# ulp_core_model: IP-XACT component
VLNV IcronTechnologies:IcronTechnologies:ulp_core_model:1.0

## Parameters
addr_width = 9
bus_width = 32

## Bus interfaces (logical=physical port)
default_map: slave AGNISYS:AGNISYS:APB:1.0, memory map ulp_coremap
  pclk=pclk, presetn=presetn, psel=psel, penable=penable, pwrite=pwrite, pprot=pprot, pstrb=pstrb, pwdata=pwdata, paddr=paddr, pready=pready, prdata=prdata, pslverr=pslverr

## Ports
in pclk
in presetn
in psel
in penable
in pwrite
in pprot[2:0]
in pstrb[(bus_width div 8 )-1:0]
in pwdata[bus_width -1:0]
in paddr[addr_width -1:0]
out pready
out prdata[bus_width -1:0]
out pslverr
out ulp_core_regsversion_major_r[7:0]
out ulp_core_regsversion_minor_r[7:0]
out ulp_core_regsversion_patch_r[7:0]
out ulp_core_regsconfiguration_enb
out ulp_core_regsconfiguration_credit_hp_timer_en_r
out ulp_core_regsconfiguration_pending_hp_timer_en_r
out ulp_core_regsconfiguration_internal_loopback_en_r
out ulp_core_regsconfiguration_quasi_ss_disabled_mode_r
out ulp_core_regsconfiguration_quasi_u3_mode_r
out ulp_core_regsconfiguration_allow_u2_r
out ulp_core_regsconfiguration_allow_u1_r
out ulp_core_regsconfiguration_dfp_compliance_mode_en_r
out ulp_core_regsconfiguration_use_trx_detect_quiet_dfp_max_r
out ulp_core_regscontrol_enb
out ulp_core_regscontrol_wait_in_polling_lfps_r
out ulp_core_regscontrol_exit_low_power_r
in ulp_core_regscontrol_exit_low_power_hw_clear
out ulp_core_regscontrol_wait_in_u3_r
out ulp_core_regscontrol_wait_in_u1_u2_r
out ulp_core_regscontrol_delay_u3_wakeup_r
out ulp_core_regscontrol_go_u{n}_r (n=1..3)
in ulp_core_regscontrol_go_u{n}_hw_clear (n=1..3)
out ulp_core_regscontrol_wait_in_hot_reset_r
out ulp_core_regscontrol_gen_warm_reset_r
in ulp_core_regscontrol_gen_warm_reset_hw_clear
out ulp_core_regscontrol_allow_rx_term_en_hw_clr_r
out ulp_core_regscontrol_rx_termination_en_r
in ulp_core_regscontrol_rx_termination_en_hw_clear
out ulp_core_regscontrol_go2_ss_inactive_r
in ulp_core_regscontrol_go2_ss_inactive_hw_clear
out ulp_core_regscontrol_go2_recovery_r
in ulp_core_regscontrol_go2_recovery_hw_clear
out ulp_core_regscontrol_go2_hot_reset_r
in ulp_core_regscontrol_go2_hot_reset_hw_clear
out ulp_core_regscontrol_go2_loopback_r
in ulp_core_regscontrol_go2_loopback_hw_clear
out ulp_core_regscontrol_go2_ss_disabled_r
in ulp_core_regscontrol_go2_ss_disabled_hw_clear
out ulp_core_regscontrol_disable_scrambling_r
out ulp_core_regscontrol_set_ts2_disable_scramble_bit_r
out ulp_core_regscontrol_set_ts2_loopbk_bit_r
out ulp_core_regscontrol_set_ts2_link_config_field_r
out ulp_core_regscontrol_go2_rx_detect_r
in ulp_core_regscontrol_go2_rx_detect_hw_clear
out ulp_core_regstimer_correction_enb
out ulp_core_regstimer_correction_add_2_cht_r[4:0]
out ulp_core_regstimer_correction_add_2_pht_r[4:0]
in ulp_core_regsltssm_state_main_state_in[3:0]
in ulp_core_regsltssm_state_main_state_in_enb
in ulp_core_regsltssm_state_sub_state_in[3:0]
in ulp_core_regsltssm_state_sub_state_in_enb
out ulp_core_regsstats0_rd2clr_config_rd_valid_out
out ulp_core_regsstats0_rd2clr_config_wr_valid_out
out ulp_core_regsstats0_tx_lfps_cnt_in_err_rd_valid_out
out ulp_core_regsstats0_rx_lfps_cnt_in_err_rd_valid_out
out ulp_core_regsstats0_tx_framer_ptp_violated_rd_valid_out
out ulp_core_regsstats0_link_training_ptp_violated_rd_valid_out
out ulp_core_regsstats0_link_command_ptp_violated_rd_valid_out
out ulp_core_regsstats0_lmp_ptp_violated_rd_valid_out
out ulp_core_regsstats0_link_command_rx_event_fifo_overflow_rd_valid_out
out ulp_core_regsstats0_link_command_rx_event_fifo_underflow_rd_valid_out
out ulp_core_regsstats0_lmp_rx_event_fifo_overflow_rd_valid_out
out ulp_core_regsstats0_lmp_rx_event_fifo_underflow_rd_valid_out
out ulp_core_regsstats0_remote_rx_hdr_buff_crdt_cnt_in_err_rd_valid_out
out ulp_core_regsstats0_to_phy_out_sop_rd_valid_out
out ulp_core_regsstats0_to_phy_out_eop_rd_valid_out
out ulp_core_regsstats0_go2_u0_from_recovery_rd_valid_out
out ulp_core_regsstats0_rx_go_recovery_rd_valid_out
out ulp_core_regsstats0_snt_lrty_rd_valid_out
out ulp_core_regsstats0_snt_lbad_rd_valid_out
out ulp_core_regsstats0_rcvd_lrty_rd_valid_out
out ulp_core_regsstats0_rcvd_lbad_rd_valid_out
out ulp_core_regsptp_guard_2core_config0_fix_ptp_violations_enb
out ulp_core_regsptp_guard_2core_config0_fix_ptp_violations_activate_r
out ulp_core_regsptp_guard_2core_config0_max_cycles_enb
out ulp_core_regsptp_guard_2core_config0_max_cycles_max_cycle_mode_r[3:0]
out ulp_core_regsptp_guard_2core_config0_max_cycles_max_cycles_r[15:0]
out ulp_core_regsptp_guard_2core_stats0_rd2clr_config_rd_valid_out
out ulp_core_regsptp_guard_2core_stats0_rd2clr_config_wr_valid_out
out ulp_core_regsptp_guard_2core_stats0_missing_sop_err_rd_valid_out
out ulp_core_regsptp_guard_2core_stats0_missing_eop_err_rd_valid_out
out ulp_core_regsptp_guard_2core_stats0_max_cycle_err_rd_valid_out
out ulp_core_regsptp_guard_2phy_config0_fix_ptp_violations_enb
out ulp_core_regsptp_guard_2phy_config0_fix_ptp_violations_activate_r
out ulp_core_regsptp_guard_2phy_config0_max_cycles_enb
out ulp_core_regsptp_guard_2phy_config0_max_cycles_max_cycle_mode_r[3:0]
out ulp_core_regsptp_guard_2phy_config0_max_cycles_max_cycles_r[15:0]
out ulp_core_regsptp_guard_2phy_stats0_rd2clr_config_rd_valid_out
out ulp_core_regsptp_guard_2phy_stats0_rd2clr_config_wr_valid_out
out ulp_core_regsptp_guard_2phy_stats0_missing_sop_err_rd_valid_out
out ulp_core_regsptp_guard_2phy_stats0_missing_eop_err_rd_valid_out
out ulp_core_regsptp_guard_2phy_stats0_max_cycle_err_rd_valid_out

## Address spaces and blocks
ulp_coremap.ulp_core: base 0x000, range 0x200, width 32

## Registers
Registers are 32-bit, read-only, reset 0x0 unless marked. A register's access mark holds for its fields unless they carry their own. Offsets are from the block's base; lines under a group give offsets from that group; [hi:lo] are bit positions; {n}, {i} and the like mark numbered series; 'fields as' and 'values as' point back to an identical list; <NAME> marks a mode.

## ulp_coremap.ulp_core — ULP Registers
Base 0x00000000
0x00 version reset 0x90000 — 8.0.1: Cleanup and add synchronizer to phy_reset_n to avoid direct path to the output pad 8.1.0: Changed the Interrupt Pending to avoid blocking the register update when enable is 0 8.2.0: Added pending_irq register 8.3.0: Fixed Hot Reset bug; Added in_u0 to the 'rdy' to the top level; Bring in_hot_reset and in_warm_reset to upper layer 8.3.1: Cap Remote RX Credit Count to 4 8.4.0: Changed from Logic to Wire for ift_ulp_pipe 8.5.0: Add Timer Corrections 8.5.1: Bug fixes 8.5.2: Bug fixes (5466, 4724, 4808) 8.5.3: Address timing issues for previous fix 8.5.4: Infinite Loop and signal reset assignment missing fixed 9.0.0: Many Enhancement and bug fixes for LFPS, Polarity Detection, RX Detect, data exception handing, U3 wakeup, register operations, etc
  [23:16] major — Major version
  [15:8] minor — Minor version
  [7:0] patch — Patch version
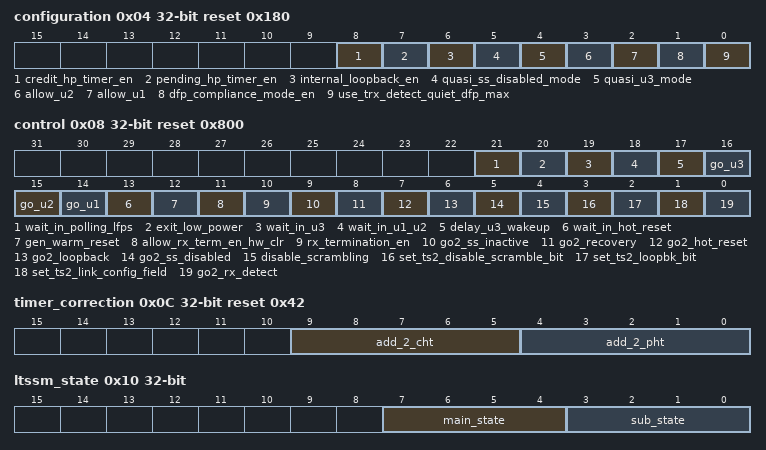
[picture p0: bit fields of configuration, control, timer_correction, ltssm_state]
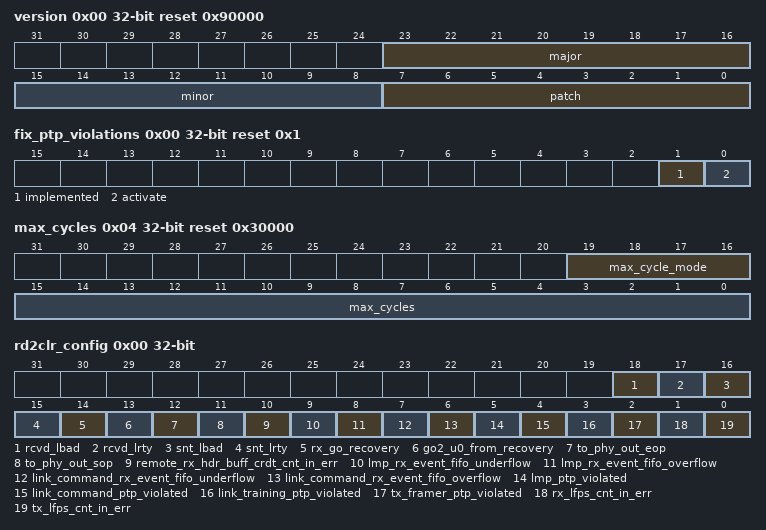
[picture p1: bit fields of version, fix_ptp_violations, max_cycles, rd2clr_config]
0x04 configuration rw reset 0x180
  [8] credit_hp_timer_en — When 1, it enables the Credit_HP_Timer
  [7] pending_hp_timer_en — When 1, it enables the Pending_HP_Timer
  [6] internal_loopback_en — When 1 it enables an RX Loopback (Section 6.8.4) implementation in the USB Link Layer rather than the PHY
  [5] quasi_ss_disabled_mode — When 1, it puts the USB PHY into P2 power mode rather than the normal P3 as required by the Standard
  [4] quasi_u3_mode — When 1, it handshakes U3 protocol with the USB partner but puts the USB PHY into P2 low power mode. This mode could be used for debugging, or in case of any bug in normal U3 mode as USB PHY PCLK is removed in U3
  [3] allow_u2 — Assert high to allow U2 Low Power request to be processed. When low, it will always issue LXU. Section 7.2.4.2.3 Item 3
  [2] allow_u1 — Assert high to allow U1 Low Power request to be processed. When low, it will always issue LXU. Section 7.2.4.2.3 Item 3
  [1] dfp_compliance_mode_en — Section 7.5.4.3.1 Item 4: A downstream port shall enable its transition path to Compliance Mode, if directed
  [0] use_trx_detect_quiet_dfp_max — Section 7.5.3.7.1 and Table 7-12 (Note 1): Implementations are recommended to consider system states when choosing when to use a larger value of the tRxDetectQuietTimeoutDFP timer. Using a smaller value when the system is active and a larger value when the system is in a standby/sleep or other idle state allows for higher responsiveness to connect events during active states while enabling power savings in an idle system state.
0x08 control rw reset 0x800
  [21] wait_in_polling_lfps — When 1, it instructs the port to wait in Polling.LFPS. Note this wait is NOT based on standard but only for LEX/REX extension benefit. Also note the 360 ms timer of this state
  [20] exit_low_power — Assert high to initiate exit from U1, U2, or U3 Low Power. Section 7.2.4.2.7 and Sections 7.5.8.2 Item 7, 7.5.8.2 Item 6, and 7.5.9.2 Item 5 Write a 1 and HW clears
  [19] wait_in_u3 — When set, allows the software to hold the port in its exit handshaking (either initiated by link partner or self initiated) to come out U3 following Section 7.2.4.2.7. Note the limit time based on Table 6-30 in Section 6.9.2. A 20ms for U3 (t13-t10)
  [18] wait_in_u1_u2 — When set, allow the software to hold the port in its exit handshaking (either initiated by link partner or self initiated) to come out U1, U2 following Section 7.2.4.2.7. Note the limit time based on Table 6-30 in Section 6.9.2. A 2ms for U1/U2 (t13-t10)
  [17] delay_u3_wakeup — Assert high to delay the start of the wakeup. This applies to both when the port is Master (initiating) of U3 wakeup or Slave (responding) to U3 wakeup. In effect, it will delay t10 of Figure 6-30 when it is Master or t11 when it is Slave. NOTE: If this bit is set when the port is a master of wakeup and remains asserted, it will result in squelching the wakeup LFPS. If it remains asserted for over 10ms, an interrupt is issued informing software of a wakeup failure, as the Slave will never see wakeup to be able to respond. Both ports will remain in U3. In this configuration, this bit can be used as a test bit as well. If this bit is et when the port is a slave of wakeup and remains asserted, the master port will see a tNOLFPSReponseTimeout and both ports remain in U3. In this configuration, this bit can be used as a test bit.
  [16] go_u3 — Assert high to initiate a U3 Low Power when in U0. Section 7.2.4.2.3 and Section 7.5.6.2 Item 3 NOTE: This can only be done when it is a downstream port. Otherwise, no action is taken Write a 1 and HW clears it
  [15] go_u2 — Assert high to initiate a U2 Low Power when in U0. Section 7.2.4.2.3 and Section 7.5.6.2 Item 2 Write a 1 and HW clears it
  [14] go_u1 — Assert high to initiate a U1 Low Power when in U0. Section 7.2.4.2.3 and Section 7.5.6.2 Item 1 Write a 1 and HW clears it
  [13] wait_in_hot_reset — When set, allows the software to kepp the port in hot reset whenever it enters and, thus, prevents the handshake of HotReset.Active in Section 7.5.12.3.2 to complete. Note the 12 ms timer for tHotResetActiveTimeout as the LTSSM will slip into eSS.Inactive from the Hot Reset state on expiry of this timer
  [12] gen_warm_reset — Section 6.9.3: A downstream port may issue a Warm Reset at any Link states except SS.Disabled. See also 10.3.1.6, the Resetting State of a Downstream Port Write a 1 and HW clears it
  [11] allow_rx_term_en_hw_clr — When set to 1, it allows the Hardware to self clear rx_termination_en when entering back into rx_termination reset. When set to 0, the hardware does not clear rx_termination_en bit at any time.
  [10] rx_termination_en — Enable presenting ULP RX termination. Set to 1 when the port is to present its RX Termination to the USB partner. Writing a 0, will remove the termination to the USB partner and enables a "stealth mode". HW clears this bit (when allow_rx_term_en_hw_clr is asserted) when the LTSSM goes into the RX.Detect.Reset
  [9] go2_ss_inactive — Section 7.5.6.2 Item 10, A downstream port shall transition to eSS.Inactive when directed Write a 1 and HW clears it
  [8] go2_recovery — Section 7.5.6.2 Item 7: The port shall transition to Recovery when directed Write a 1 and HW clears it
  [7] go2_hot_reset — Section 7.5.10.5.2 Item 5: A downstream port shall transition to Hot Reset when directed Write a 1 and HW clears it when completed the action
  [6] go2_loopback — Section 7.5.4.10.2 Item 1, 7.5.10.5.2 Item 1: The port shall transition to Loopback when directed as a loopback master and the port is capable of being a loopback master Write a 1 and HW clears it when completed the action NOTE: Not Implemented, as we are always a loopback slave
  [5] go2_ss_disabled — Sections 7.5.6.2 Item 11 , 7.5.2.3.2 , 7.5.3.3.2, 7.5.3.6, 7.5.3.7.2, 7.5.4.3.2, 7.5.4.7.2, 7.5.4.8.2 Item 10, 7.5.4.9.2 Item 10, 7.5.4.10.2 Item 6, 7.5.6.2 Item 9, 7.5.6.2 Item 11, 7.5.10.3.2 Item 5, 7.5.10.4.2 Item 5, 7.5.10.5.2 Item 6 Write a 1 and HW clears it.
  [4] disable_scrambling — Section 7.5.4.10.1 Item 5: ( This is for the TX Scrambler) The port in SuperSpeed operation shall disable the scrambling if directed
  [3] set_ts2_disable_scramble_bit — Section 7.5.4.9.1 Item 1.3: When directed, the port shall set the Disabling Scrambling bit in the TS2 ordered set. This shall eventually be used in the RX De-Scrambler
  [2] set_ts2_loopbk_bit — Not Used -Will be Removed
  [1] set_ts2_link_config_field — Not Used -Will be Removed
  [0] go2_rx_detect — Section 7.5.1.1.2 Item 1: A downstream port shall transition to Rx.Detect when directed Write a 1 and HW clears it.
0x0C timer_correction rw reset 0x42
  [9:5] add_2_cht — Each value adds (2^13)*8 ns (8 is the result of the block running at 125MHz) to the CREDIT_HP_TIMER of Table 7-7. Hence, value of 2 adds 2*8192*8=131.072us
  [4:0] add_2_pht — Each value adds (2^5)*8 ns (8 is the result of the block running at 125MHz) to the PENDING_HP_TIMER of Table 7-7. Hence, value of 2 adds 2*32*8=512ns
0x10 ltssm_state — Shows the LTSSM State at the time
  [7:4] main_state — This is the main state of the LTSSM as listed in the Standard Section 7.5
  [3:0] sub_state — This is the sub state of the LTSSM as listed in the Standard Section 7.5
0x14 stats0 group — All the Statistic Registers and their configuration for the ULP Core Clock
  0x00 rd2clr_config rw — Configures if the stats register read by s/w clears the read register. A 1 in any bit configures the h/w to clear the corresponding stats register after a s/w read of that stats register.
    [18] rcvd_lbad, [17] rcvd_lrty, [16] snt_lbad, [15] snt_lrty, [14] rx_go_recovery, [13] go2_u0_from_recovery, [12] to_phy_out_eop, [11] to_phy_out_sop, [10] remote_rx_hdr_buff_crdt_cnt_in_err, [9] lmp_rx_event_fifo_underflow, [8] lmp_rx_event_fifo_overflow, [7] link_command_rx_event_fifo_underflow, [6] link_command_rx_event_fifo_overflow, [5] lmp_ptp_violated, [4] link_command_ptp_violated, [3] link_training_ptp_violated, [2] tx_framer_ptp_violated, [1] rx_lfps_cnt_in_err, [0] tx_lfps_cnt_in_err
  0x04 tx_lfps_cnt_in_err — Count of the number of TX LFPS counter going beyond the largest value possible
    [7:0] tx_lfps_cnt_in_err
  0x08 rx_lfps_cnt_in_err — Count of the number of RX LFPS counter going beyond the largest value possible
    [7:0] rx_lfps_cnt_in_err
  0x0C tx_framer_ptp_violated — Count the number of PTP Protocol Violation in the TX Frame Manager
    [7:0] tx_framer_ptp_violated — _icron_event_detect_rising_edge_
  0x10 link_training_ptp_violated — Count the number of PTP Protocol Violation in the Link Training Manager
    [7:0] link_training_ptp_violated — _icron_event_detect_rising_edge_
  0x14 link_command_ptp_violated — Count the number of PTP Protocol Violation in the Link Command Manager
    [7:0] link_command_ptp_violated — _icron_event_detect_rising_edge_
  0x18 lmp_ptp_violated — Count the number of PTP Protocol Violation in the LMP Manager
    [7:0] lmp_ptp_violated
  0x1C link_command_rx_event_fifo_overflow — Count the number of Link Command RX Event FIFO Overflow
    [7:0] link_command_rx_event_fifo_overflow
  0x20 link_command_rx_event_fifo_underflow — Count the number of Link Command RX Event FIFO Underflow
    [7:0] link_command_rx_event_fifo_underflow
  0x24 lmp_rx_event_fifo_overflow — Count the number of LMP Manager RX Event FIFO Overflow
    [7:0] lmp_rx_event_fifo_overflow
  0x28 lmp_rx_event_fifo_underflow — Count the number of LMP Manager RX Event FIFO Underflow
    [7:0] lmp_rx_event_fifo_underflow
  0x2C remote_rx_hdr_buff_crdt_cnt_in_err — Count the number of Remote RX Header Buffer Credit Count erroneous increment or decrement
    [7:0] remote_rx_hdr_buff_crdt_cnt_in_err
  0x30 to_phy_out_sop — Count the number of PTP sop to the PHY path
  0x34 to_phy_out_eop — Count the number of PTP eop to the PHY path
  0x38 go2_u0_from_recovery — Count of the number of times LTSSM move from Recovery to U0
    [15:0] go2_u0_from_recovery
  0x3C rx_go_recovery — Count of the number of recovery initiated due to received data from PHY (Section 7.6.6.2 Item 5)
    [15:0] rx_go_recovery
  0x40 snt_lrty — Count of the number of times the ULP has sent LRTY to its partner in response to receiving LBAD from its partner
    [15:0] snt_lrty
  0x44 snt_lbad — Count of the number of times the ULP has sent LBAD to its partner
    [15:0] snt_lbad
  0x48 rcvd_lrty — Count of the number of times the ULP has received LRTY from its partner in response to an earlier ULP sending LBAD
    [15:0] rcvd_lrty
  0x4C rcvd_lbad — Count of the number of times the ULP has received LBAD from its partner
    [15:0] rcvd_lbad
0x64 ptp_guard_2core group
  0x00 version reset 0x30300 — 3.1.0: Fixed bug in Max Cycle Error where in certain mode the cycles were included in the count 3.2.0: Changed the Interrupt Pending to avoid blocking the register update when enable is 0 3.3.0: Added pending_irq register
    fields as version
  0x04 config0 group
    0x00 fix_ptp_violations access per field reset 0x1
      [1] implemented ro — This is the synthesis parameter value used. When 1, it shows the PTP Guard fix logic has been implemented
      [0] activate rw — When 1, and if the fix logic is implemented, it instructs the PTP Guard to fix the PTP violations it detects (and reports). Note that there is a synthesis parameter to generate the "fix" logic or not When 0, no attempt is done to fix (even if the logic exists) and the PTP Guard will only work as a monitor and reports the violations detected. For full details of the operation, what violations are detected and fixed, and how the fix is done, see the wiki.
    0x04 max_cycles rw reset 0x30000
      [19:16] max_cycle_mode — This configures the mode of counting towards max_cycles: 0x0: All PTP cycles are included in the count 0x1: PTP cycles with backpressure (drdy=1'b0) are excluded from the count 0x2: PTP cycles with wait (srdy=1'b0) are excluded from the count 0x3: PTP cycles with either backpressure or wait are excluded from the count. Hence, only "absorbed" PTP cycles are included in the count Other mode values are reserved
      [15:0] max_cycles — Sets the maximum number of clock cycles the PTP packet can last between its sop and eop taking into account the max_cycle_mode When set to 0, it instructs the logic not to fix this violation (when the fix logic is available). However, the monitor will still issue a violation when the cycle count reaches its maximum and rollover.
  0x0C stats0 group — All the Statistic Registers and their configuration
    0x00 rd2clr_config rw — Configures if the stats register read by s/w clears the read register. A 1 in any bit configures the h/w to clear the corresponding stats register after a s/w read of that stats register.
      [2] max_cycle_err, [1] missing_eop_err, [0] missing_sop_err
    0x04 missing_sop_err — Counts the number of PTP violations due to missing sop where the srdy was asserted without a prior sop assertion
      [15:0] missing_sop_err
    0x08 missing_eop_err — Counts the number of PTP violations due to missing eop where the PTP had been started but a new sop is seen without ending the previously started PTP
      [15:0] missing_eop_err
    0x0C max_cycle_err — Counts the number of PTP violations due to reaching the maximum allowed cycles after starting a new PTP
      [15:0] max_cycle_err
  0x1C irq0 group — Define the IRQ group
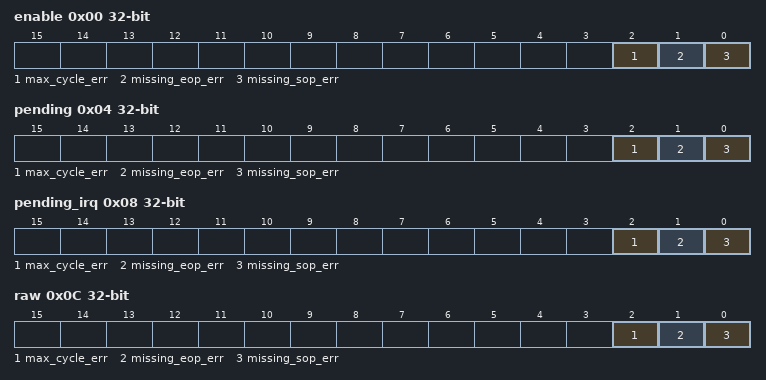
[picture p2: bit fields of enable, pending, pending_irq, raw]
    0x00 enable rw — The enable for the actual interrupt signals. Writing a 1 enables the interrupt.
      [2] max_cycle_err — Fires on PTP violations due to reaching the maximum allowed cycles after starting a new PTP
      [1] missing_eop_err — Fires on PTP violations due to missing eop where the PTP had been started but a new sop is seen without ending the previously started PTP
      [0] missing_sop_err — Fires on PTP violations due to missing sop where the srdy was asserted without a prior sop assertion
    0x04 pending rw — The actual interrupt(s) that has triggered. Write a 1 to clear.
      [2] max_cycle_err write-1-clears, [1] missing_eop_err write-1-clears, [0] missing_sop_err write-1-clears
    0x08 pending_irq — Registered version of pending & enable.
      [2] max_cycle_err, [1] missing_eop_err, [0] missing_sop_err
    0x0C raw — The status registered values for the interrupt signals, if applicable.
      [2] max_cycle_err — Not used
      [1] missing_eop_err — Not used
      [0] missing_sop_err — Not used
0x90 ptp_guard_2phy group
  0x00 version reset 0x30300 — 3.1.0: Fixed bug in Max Cycle Error where in certain mode the cycles were included in the count 3.2.0: Changed the Interrupt Pending to avoid blocking the register update when enable is 0 3.3.0: Added pending_irq register
    fields as version
  0x04 config0 group
    0x00 fix_ptp_violations access per field reset 0x1
      fields as ptp_guard_2core.config0.fix_ptp_violations
    0x04 max_cycles rw reset 0x30000
      fields as ptp_guard_2core.config0.max_cycles
  0x0C stats0 group — All the Statistic Registers and their configuration
    0x00 rd2clr_config rw — Configures if the stats register read by s/w clears the read register. A 1 in any bit configures the h/w to clear the corresponding stats register after a s/w read of that stats register.
      [2] max_cycle_err, [1] missing_eop_err, [0] missing_sop_err
    0x04 missing_sop_err — Counts the number of PTP violations due to missing sop where the srdy was asserted without a prior sop assertion
      [15:0] missing_sop_err
    0x08 missing_eop_err — Counts the number of PTP violations due to missing eop where the PTP had been started but a new sop is seen without ending the previously started PTP
      [15:0] missing_eop_err
    0x0C max_cycle_err — Counts the number of PTP violations due to reaching the maximum allowed cycles after starting a new PTP
      [15:0] max_cycle_err
  0x1C irq0 group — Define the IRQ group
    0x00 enable rw — The enable for the actual interrupt signals. Writing a 1 enables the interrupt.
      fields as ptp_guard_2core.irq0.enable
    0x04 pending rw — The actual interrupt(s) that has triggered. Write a 1 to clear.
      fields as ptp_guard_2core.irq0.pending
    0x08 pending_irq — Registered version of pending & enable.
      [2] max_cycle_err, [1] missing_eop_err, [0] missing_sop_err
    0x0C raw — The status registered values for the interrupt signals, if applicable.
      fields as ptp_guard_2core.irq0.raw
0xBC irq0 group — Define the IRQ group
  0x00 enable rw — The enable for the actual interrupt signals. Writing a 1 enables the interrupt.
    [29] core_clk_mode — Fires when the core clock mode changes from system 125 to the derivative of the PCLK (1/2PCLK) or vice-versa
    [28] u3_exit_completed — Fires when the U1/U2 or U3 wakeup is successfully complete
    [27] u3_as_slave_exit_failed — When Salve of exit, it fires on when U3 wakeup does not complete. This is typically is the case when the port is configured to not start its wakeup LFPS (delay t11 of Figure 6-30) before 10 ms limit.
    [26] u3_as_master_exit_failed — When Master of exit, it fires on when the U1/U2 exit or U3 wakeup does not complete correctly due to tNOLFPSReponseTimeout. --See Section 7.2.4.2.7 Item 5 and Item 6
    [25] u3_exit_initiated — Fires on when a U1/U2 exit or U3 wakeup is received
    [24] in_u3 — Fires on when entered U3
    [23] u3_entry_failed — Fires on when our U3 does not complete and we end up in LTSSM Inactive. (NOT CONNECTED) --see Section 7.2.4.2.4 Item 11
    [22] u3_entry_received — Fires on when a U3 Request is received from the USB partner Note that only a downstream partner will issue U3
    [21] in_u2 — Fires on when entered U2
    [20] u2_entry_rejected — Fires on when our U2 request is rejected by the USB partner
    [19] u2_entry_received — Fires on when a U2 Request is received from the USB partner
    [18] in_u1 — Fires on when entered U1
    [17] u1_entry_rejected — Fires on when our U1 request is rejected by the USB partner
    [16] u1_entry_received — Fires on when a U1 Request is received from the USB partner
    [15] completed_hot_reset — Fires on completing the hot reset
    [14] in_hot_reset — Fires on entry into hot reset
    [13] completed_warm_reset — Fires on completing the warm reset
    [12] in_warm_reset — Fires on entry into warm reset
    [11] rx_termination_det — Fires on changing the state of the USB partner's RX Termination
    [10] remote_rx_hdr_buff_crdt_cnt_in_err — Fires on Remote RX Header Buffer Credit Count erroneous increment or decrement
    [9] lmp_rx_event_fifo_underflow — Fires on LMP Manager RX Event FIFO Underflow
    [8] lmp_rx_event_fifo_overflow — Fires on LMP Manager RX Event FIFO Overflow
    [7] link_command_rx_event_fifo_underflow — Fires on Link Command RX Event FIFO Underflow
    [6] link_command_rx_event_fifo_overflow — Fires on Link Command RX Event FIFO Overflow
    [5] lmp_ptp_violated — Fires on PTP Protocol Violation in the LMP Manager
    [4] link_command_ptp_violated — Fires on PTP Protocol Violation in the Link Command Manager
    [3] link_training_ptp_violated — Fires on PTP Protocol Violation in the Link Training Manager
    [2] tx_framer_ptp_violated — Fires on PTP Protocol Violation in the TX Frame Manager
    [1] rx_lfps_cnt_in_err — Fires on RX LFPS counter going beyond the largest value possible
    [0] tx_lfps_cnt_in_err — Fires on TX LFPS counter going beyond the largest value possible
  0x04 pending rw — The actual interrupt(s) that has triggered. Write a 1 to clear.
    [29] core_clk_mode write-1-clears — Fires when the core clock mode changes from system 125 to the derivative of the PCLK (1/2PCLK) or vice-versa
    [28] u3_exit_completed write-1-clears — Fires when the U1/U2 or U3 wakeup is successfully complete
    [27] u3_as_slave_exit_failed write-1-clears — When Salve of exit, it fires on when U3 wakeup does not complete. This is typically is the case when the port is configured to not start its wakeup LFPS (delay t11 of Figure 6-30) before 10 ms limit.
    [26] u3_as_master_exit_failed write-1-clears — When Master of exit, it fires on when the U1/U2 exit or U3 wakeup does not complete correctly due to tNOLFPSReponseTimeout. --See Section 7.2.4.2.7 Item 5 and Item 6
    [25] u3_exit_initiated write-1-clears — Fires on when a U1/U2 exit or U3 wakeup is received
    [24] in_u3 write-1-clears — Fires on when entered U3
    [23] u3_entry_failed write-1-clears — Fires on when our U3 does not complete and we end up in LTSSM Inactive --see Section 7.2.4.2.4 Item 11
    [22] u3_entry_received write-1-clears — Fires on when a U3 Request is received from the USB partner Note that only a downstream partner will issue U3
    [21] in_u2 write-1-clears — Fires on when entered U2
    [20] u2_entry_rejected write-1-clears — Fires on when our U2 request is rejected by the USB partner
    [19] u2_entry_received write-1-clears — Fires on when a U2 Request is received from the USB partner
    [18] in_u1 write-1-clears — Fires on when entered U1
    [17] u1_entry_rejected write-1-clears — Fires on when our U1 request is rejected by the USB partner
    [16] u1_entry_received write-1-clears — Fires on when a U1 Request is received from the USB partner
    [15] completed_hot_reset write-1-clears — Fires on completing the hot reset
    [14] in_hot_reset write-1-clears — Fires on entry into hot reset
    [13] completed_warm_reset write-1-clears — Fires on completing the warm reset
    [12] in_warm_reset write-1-clears — Fires on entry into warm reset
    [11] rx_termination_det write-1-clears — Fires on changing the state of the USB partner's RX Termination
    [10] remote_rx_hdr_buff_crdt_cnt_in_err write-1-clears — Fires on Remote RX Header Buffer Credit Count erroneous increment or decrement
    [9] lmp_rx_event_fifo_underflow write-1-clears — Fires on LMP Manager RX Event FIFO Underflow
    [8] lmp_rx_event_fifo_overflow write-1-clears — Fires on LMP Manager RX Event FIFO Overflow
    [7] link_command_rx_event_fifo_underflow write-1-clears — Fires on Link Command RX Event FIFO Underflow
    [6] link_command_rx_event_fifo_overflow write-1-clears — Fires on Link Command RX Event FIFO Overflow
    [5] lmp_ptp_violated write-1-clears — Fires on PTP Protocol Violation in the LMP Manager
    [4] link_command_ptp_violated write-1-clears — Fires on PTP Protocol Violation in the Link Command Manager
    [3] link_training_ptp_violated write-1-clears — Fires on PTP Protocol Violation in the Link Training Manager
    [2] tx_framer_ptp_violated write-1-clears — Fires on PTP Protocol Violation in the TX Frame Manager
    [1] rx_lfps_cnt_in_err write-1-clears — Fires on RX LFPS counter going beyond the largest value possible
    [0] tx_lfps_cnt_in_err write-1-clears — Fires on TX LFPS counter going beyond the largest value possible
  0x08 pending_irq — Registered version of pending & enable
    [29] core_clk_mode — Fires when the core clock mode changes from system 125 to the derivative of the PCLK (1/2PCLK) or vice-versa
    [28] u3_exit_completed — Fires when the U1/U2 or U3 wakeup is successfully complete
    [27] u3_as_slave_exit_failed — When Salve of exit, it fires on when U3 wakeup does not complete. This is typically is the case when the port is configured to not start its wakeup LFPS (delay t11 of Figure 6-30) before 10 ms limit.
    [26] u3_as_master_exit_failed — When Master of exit, it fires on when the U1/U2 exit or U3 wakeup does not complete correctly due to tNOLFPSReponseTimeout. --See Section 7.2.4.2.7 Item 5 and Item 6
    [25] u3_exit_initiated — Fires on when a U1/U2 exit or U3 wakeup is received
    [24] in_u3 — Fires on when entered U3
    [23] u3_entry_failed — Fires on when our U3 does not complete and we end up in LTSSM Inactive --see Section 7.2.4.2.4 Item 11
    [22] u3_entry_received — Fires on when a U3 Request is received from the USB partner Note that only a downstream partner will issue U3
    [21] in_u2 — Fires on when entered U2
    [20] u2_entry_rejected — Fires on when our U2 request is rejected by the USB partner
    [19] u2_entry_received — Fires on when a U2 Request is received from the USB partner
    [18] in_u1 — Fires on when entered U1
    [17] u1_entry_rejected — Fires on when our U1 request is rejected by the USB partner
    [16] u1_entry_received — Fires on when a U1 Request is received from the USB partner
    [15] completed_hot_reset — Fires on completing the hot reset
    [14] in_hot_reset — Fires on entry into hot reset
    [13] completed_warm_reset — Fires on completing the warm reset
    [12] in_warm_reset — Fires on entry into warm reset
    [11] rx_termination_det — Fires on changing the state of the USB partner's RX Termination
    [10] remote_rx_hdr_buff_crdt_cnt_in_err — Fires on Remote RX Header Buffer Credit Count erroneous increment or decrement
    [9] lmp_rx_event_fifo_underflow — Fires on LMP Manager RX Event FIFO Underflow
    [8] lmp_rx_event_fifo_overflow — Fires on LMP Manager RX Event FIFO Overflow
    [7] link_command_rx_event_fifo_underflow — Fires on Link Command RX Event FIFO Underflow
    [6] link_command_rx_event_fifo_overflow — Fires on Link Command RX Event FIFO Overflow
    [5] lmp_ptp_violated — Fires on PTP Protocol Violation in the LMP Manager
    [4] link_command_ptp_violated — Fires on PTP Protocol Violation in the Link Command Manager
    [3] link_training_ptp_violated — Fires on PTP Protocol Violation in the Link Training Manager
    [2] tx_framer_ptp_violated — Fires on PTP Protocol Violation in the TX Frame Manager
    [1] rx_lfps_cnt_in_err — Fires on RX LFPS counter going beyond the largest value possible
    [0] tx_lfps_cnt_in_err — Fires on TX LFPS counter going beyond the largest value possible
  0x0C raw — The status registered values for the interrupt signals, if applicable.
    [29] core_clk_mode — Shows the status of the clock source for the ULP core. When 0, the source is from system 125 When 1, it is the 125 derived from the PCLK (250)
    [28] u3_exit_completed — Not used
    [27] u3_as_slave_exit_failed — Not used
    [26] u3_as_master_exit_failed — Not used
    [25] u3_exit_initiated — Not used
    [24] in_u3 — Not used
    [23] u3_entry_failed — Not used
    [22] u3_entry_received — Not used
    [21] in_u2 — Not used
    [20] u2_entry_rejected — Not used
    [19] u2_entry_received — Not used
    [18] in_u1 — Not used
    [17] u1_entry_rejected — Not used
    [16] u1_entry_received — Not used
    [15] completed_hot_reset — Not used
    [14] in_hot_reset — Not used
    [13] completed_warm_reset — Not used
    [12] in_warm_reset — Not used
    [11] rx_termination_det — Shows the status of the USB partner's RX Termination. When 1, the termination has been detected. When 0, no termination detected
    [10] remote_rx_hdr_buff_crdt_cnt_in_err — Not used
    [9] lmp_rx_event_fifo_underflow — Not used
    [8] lmp_rx_event_fifo_overflow — Not used
    [7] link_command_rx_event_fifo_underflow — Not used
    [6] link_command_rx_event_fifo_overflow — Not used
    [5] lmp_ptp_violated — Not used
    [4] link_command_ptp_violated — Not used
    [3] link_training_ptp_violated — Not used
    [2] tx_framer_ptp_violated — Not used
    [1] rx_lfps_cnt_in_err — Not used
    [0] tx_lfps_cnt_in_err — Not used
0xCC irq1 group — Define the IRQ group
  0x00 enable rw — The enable for the actual interrupt signals. Writing a 1 enables the interrupt.
    [7] in_recovery — Fires on entering into LTSSM Recovery
    [6] in_loopback — Fires on entering into LTSSM Loopback
    [5] in_compliance — Fires on entering into LTSSM Compliance Mode
    [4] in_disabled — Fires on entering into LTSSM eSS.Disabled
    [3] in_u0 — Fires on entering into LTSSM U0
    [2] in_polling — Fires on entering into LTSSM Polling
    [1] in_rx_detect — Fires on entering into LTSSM RX.Detect
    [0] in_inactive — Fires on entering into LTSSM eSS.Inactive
  0x04 pending rw — The actual interrupt(s) that has triggered. Write a 1 to clear.
    [7] in_recovery write-1-clears, [6] in_loopback write-1-clears, [5] in_compliance write-1-clears, [4] in_disabled write-1-clears, [3] in_u0 write-1-clears, [2] in_polling write-1-clears, [1] in_rx_detect write-1-clears, [0] in_inactive write-1-clears
  0x08 pending_irq — Registered version of pending & enable
    [7] in_recovery, [6] in_loopback, [5] in_compliance, [4] in_disabled, [3] in_u0, [2] in_polling, [1] in_rx_detect, [0] in_inactive
  0x0C raw — The status registered values for the interrupt signals, if applicable.
    fields as irq1.enable
